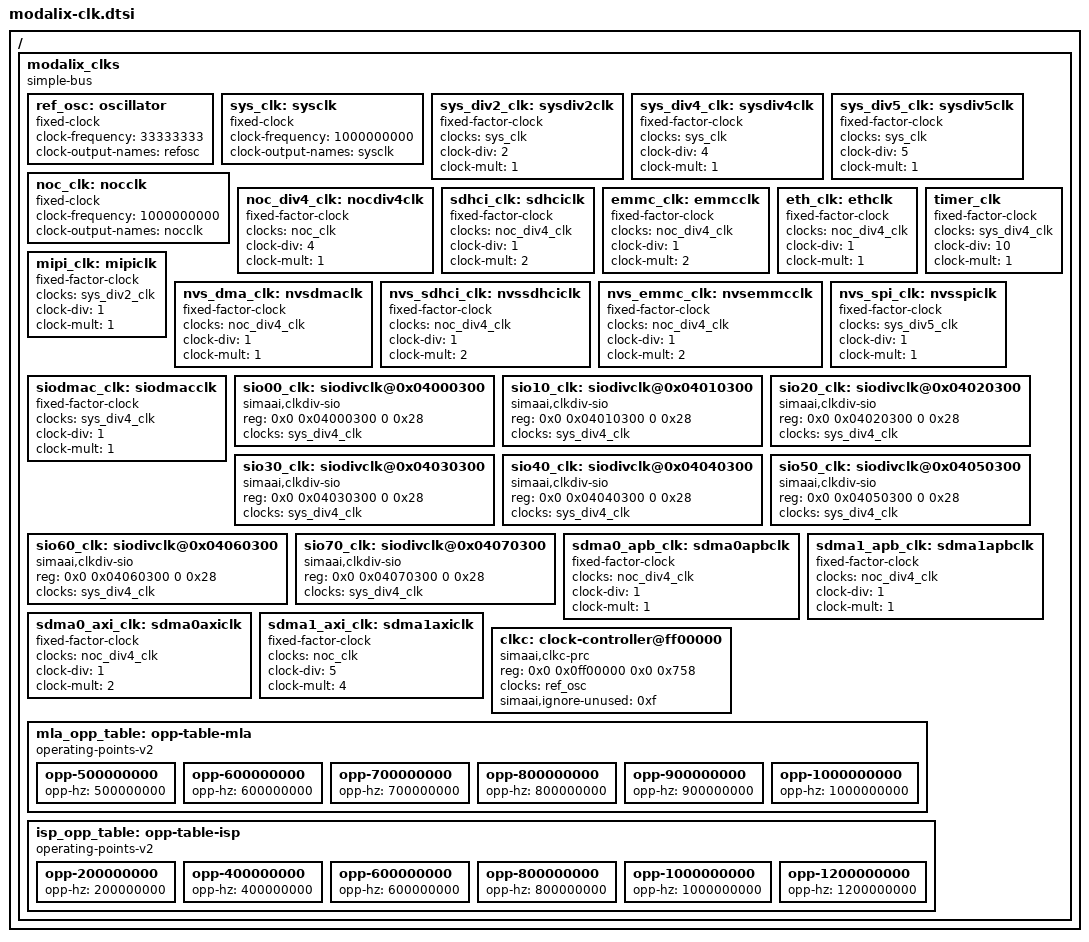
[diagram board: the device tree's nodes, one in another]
// SPDX-License-Identifier: (GPL-2.0+ OR MIT)
/*
 * Copyright (c) 2023 SiMa ai
 */

/ {
	modalix_clks {
		compatible = "simple-bus";
		#address-cells = <2>;
		#size-cells = <2>;
		ranges;

		ref_osc: oscillator {
			compatible = "fixed-clock";
			#clock-cells = <0>;
			clock-frequency = <33333333>; /* 33.33 MHz */
			clock-output-names = "refosc";
		};

		sys_clk: sysclk {
			compatible = "fixed-clock";
			#clock-cells = <0>;
			clock-frequency = <1000000000>;
			clock-output-names = "sysclk";
		};

		sys_div2_clk: sysdiv2clk {
			compatible = "fixed-factor-clock";
			clocks = <&sys_clk>;
			#clock-cells = <0>;
			clock-div = <2>;
			clock-mult = <1>;
		};

		sys_div4_clk: sysdiv4clk {
			compatible = "fixed-factor-clock";
			clocks = <&sys_clk>;
			#clock-cells = <0>;
			clock-div = <4>;
			clock-mult = <1>;
		};

		sys_div5_clk: sysdiv5clk {
			compatible = "fixed-factor-clock";
			clocks = <&sys_clk>;
			#clock-cells = <0>;
			clock-div = <5>;
			clock-mult = <1>;
		};

		noc_clk: nocclk {
			compatible = "fixed-clock";
			#clock-cells = <0>;
			clock-frequency = <1000000000>;
			clock-output-names = "nocclk";
		};

		noc_div4_clk: nocdiv4clk {
			compatible = "fixed-factor-clock";
			clocks = <&noc_clk>;
			#clock-cells = <0>;
			clock-div = <4>;
			clock-mult = <1>;
		};

		sdhci_clk: sdhciclk {
			compatible = "fixed-factor-clock";
			clocks = <&noc_div4_clk>;
			#clock-cells = <0>;
			clock-div = <1>;
			clock-mult = <2>;
		};

		emmc_clk: emmcclk {
			compatible = "fixed-factor-clock";
			clocks = <&noc_div4_clk>;
			#clock-cells = <0>;
			clock-div = <1>;
			clock-mult = <2>;
		};

		eth_clk: ethclk {
			compatible = "fixed-factor-clock";
			clocks = <&noc_div4_clk>;
			#clock-cells = <0>;
			clock-div = <1>;
			clock-mult = <1>;
		};

		timer_clk: timer_clk {
			compatible = "fixed-factor-clock";
			clocks = <&sys_div4_clk>;
			#clock-cells = <0>;
			clock-div = <10>;
			clock-mult = <1>;
		};

		mipi_clk: mipiclk {
			compatible = "fixed-factor-clock";
			clocks = <&sys_div2_clk>;
			#clock-cells = <0>;
			clock-div = <1>;
			clock-mult = <1>;
		};

		nvs_dma_clk: nvsdmaclk {
			compatible = "fixed-factor-clock";
			clocks = <&noc_div4_clk>;
			#clock-cells = <0>;
			clock-div = <1>;
			clock-mult = <1>;
		};

		nvs_sdhci_clk: nvssdhciclk {
			compatible = "fixed-factor-clock";
			clocks = <&noc_div4_clk>;
			#clock-cells = <0>;
			clock-div = <1>;
			clock-mult = <2>;
		};

		nvs_emmc_clk: nvsemmcclk {
			compatible = "fixed-factor-clock";
			clocks = <&noc_div4_clk>;
			#clock-cells = <0>;
			clock-div = <1>;
			clock-mult = <2>;
		};

		nvs_spi_clk: nvsspiclk {
			compatible = "fixed-factor-clock";
			clocks = <&sys_div5_clk>;
			#clock-cells = <0>;
			clock-div = <1>;
			clock-mult = <1>;
		};

		siodmac_clk: siodmacclk {
			compatible = "fixed-factor-clock";
			clocks = <&sys_div4_clk>;
			#clock-cells = <0>;
			clock-div = <1>;
			clock-mult = <1>;
		};

		sio00_clk: siodivclk@0x04000300 {
			compatible = "simaai,clkdiv-sio";
			reg = <0x0 0x04000300 0 0x28>;
			#clock-cells = <1>;
			clocks = <&sys_div4_clk>;
		};

		sio10_clk: siodivclk@0x04010300 {
			compatible = "simaai,clkdiv-sio";
			reg = <0x0 0x04010300 0 0x28>;
			#clock-cells = <1>;
			clocks = <&sys_div4_clk>;
		};

		sio20_clk: siodivclk@0x04020300 {
			compatible = "simaai,clkdiv-sio";
			reg = <0x0 0x04020300 0 0x28>;
			#clock-cells = <1>;
			clocks = <&sys_div4_clk>;
		};

		sio30_clk: siodivclk@0x04030300 {
			compatible = "simaai,clkdiv-sio";
			reg = <0x0 0x04030300 0 0x28>;
			#clock-cells = <1>;
			clocks = <&sys_div4_clk>;
		};

		sio40_clk: siodivclk@0x04040300 {
			compatible = "simaai,clkdiv-sio";
			reg = <0x0 0x04040300 0 0x28>;
			#clock-cells = <1>;
			clocks = <&sys_div4_clk>;
		};

		sio50_clk: siodivclk@0x04050300 {
			compatible = "simaai,clkdiv-sio";
			reg = <0x0 0x04050300 0 0x28>;
			#clock-cells = <1>;
			clocks = <&sys_div4_clk>;
		};

		sio60_clk: siodivclk@0x04060300 {
			compatible = "simaai,clkdiv-sio";
			reg = <0x0 0x04060300 0 0x28>;
			#clock-cells = <1>;
			clocks = <&sys_div4_clk>;
		};

		sio70_clk: siodivclk@0x04070300 {
			compatible = "simaai,clkdiv-sio";
			reg = <0x0 0x04070300 0 0x28>;
			#clock-cells = <1>;
			clocks = <&sys_div4_clk>;
		};

		sdma0_apb_clk: sdma0apbclk {
			compatible = "fixed-factor-clock";
			clocks = <&noc_div4_clk>;
			#clock-cells = <0>;
			clock-div = <1>;
			clock-mult = <1>;
		};

		sdma1_apb_clk: sdma1apbclk {
			compatible = "fixed-factor-clock";
			clocks = <&noc_div4_clk>;
			#clock-cells = <0>;
			clock-div = <1>;
			clock-mult = <1>;
		};

		sdma0_axi_clk: sdma0axiclk {
			compatible = "fixed-factor-clock";
			clocks = <&noc_div4_clk>;
			#clock-cells = <0>;
			clock-div = <1>;
			clock-mult = <2>;
		};

		sdma1_axi_clk: sdma1axiclk {
			compatible = "fixed-factor-clock";
			clocks = <&noc_clk>;
			#clock-cells = <0>;
			clock-div = <5>;
			clock-mult = <4>;
		};
		clkc: clock-controller@ff00000 {
			compatible = "simaai,clkc-prc";
			reg = <0x0 0x0ff00000 0x0 0x758>;
			clocks = <&ref_osc>;
			simaai,ignore-unused = <0xf>;
			#clock-cells = <1>;
		};

		mla_opp_table: opp-table-mla {
			compatible = "operating-points-v2";

			opp-500000000 { opp-hz = /bits/ 64 <500000000>; };
			opp-600000000 { opp-hz = /bits/ 64 <600000000>; };
			opp-700000000 { opp-hz = /bits/ 64 <700000000>; };
			opp-800000000 { opp-hz = /bits/ 64 <800000000>; };
			opp-900000000 { opp-hz = /bits/ 64 <900000000>; };
			opp-1000000000 { opp-hz = /bits/ 64 <1000000000>; };
		};

		isp_opp_table: opp-table-isp {
			compatible = "operating-points-v2";

			opp-200000000 { opp-hz = /bits/ 64 <200000000>; };
			opp-400000000 { opp-hz = /bits/ 64 <400000000>; };
			opp-600000000 { opp-hz = /bits/ 64 <600000000>; };
			opp-800000000 { opp-hz = /bits/ 64 <800000000>; };
			opp-1000000000 { opp-hz = /bits/ 64 <1000000000>; };
			opp-1200000000 { opp-hz = /bits/ 64 <1200000000>; };
		};
	};
};
